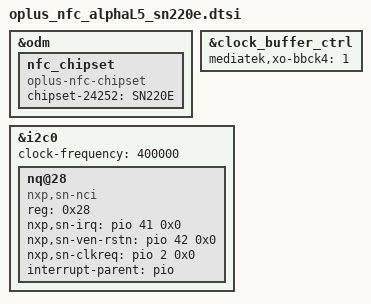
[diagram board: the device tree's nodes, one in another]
/**********************************************************************************
* Copyright (c)  2008-2020  Guangdong oplus Mobile Comm Corp., Ltd
*
***********************************************************************************/
&odm {
        nfc_chipset:nfc_chipset {
                compatible = "oplus-nfc-chipset";
                chipset-24252 = "SN220E";
                //manifest = "/odm/etc/vintf/manifest_nfc_sn100t.xml";
        };
};

&clock_buffer_ctrl {
	mediatek,xo-bbck4 = <1>;
};

&i2c0 {
       status = "okay";
       clock-frequency = <400000>;
       nq@28 {
               compatible = "nxp,sn-nci";
               reg = <0x28>;
               nxp,sn-irq = <&pio 41 0x0>;
               nxp,sn-ven-rstn = <&pio 42 0x0>;
			   nxp,sn-clkreq = <&pio 2 0x0>;
               //nxp,sn-dwl-req = <&pio 22 0x0>;
               interrupt-parent = <&pio>;
       };
};
